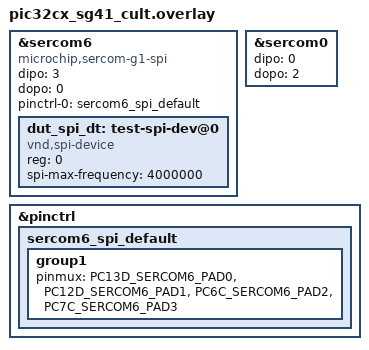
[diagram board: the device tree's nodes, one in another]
/*
 * Copyright (c) 2026 Microchip Technology Inc.
 *
 * SPDX-License-Identifier: Apache-2.0
 */

&sercom6 {
	compatible = "microchip,sercom-g1-spi";
	dipo = <3>;
	dopo = <0>;
	#address-cells = <1>;
	#size-cells = <0>;
	pinctrl-0 = <&sercom6_spi_default>;
	pinctrl-names = "default";
	status = "okay";

	dut_spi_dt: test-spi-dev@0 {
		compatible = "vnd,spi-device";
		reg = <0>;
		spi-max-frequency = <4000000>;
	};
};

dut_spis: &sercom0 {
	dipo = <0>;
	dopo = <2>;
};

&pinctrl {
	sercom6_spi_default: sercom6_spi_default {
		group1 {
			pinmux = <PC13D_SERCOM6_PAD0>,
				 <PC12D_SERCOM6_PAD1>,
				 <PC6C_SERCOM6_PAD2>,
				 <PC7C_SERCOM6_PAD3>;
		};
	};
};
